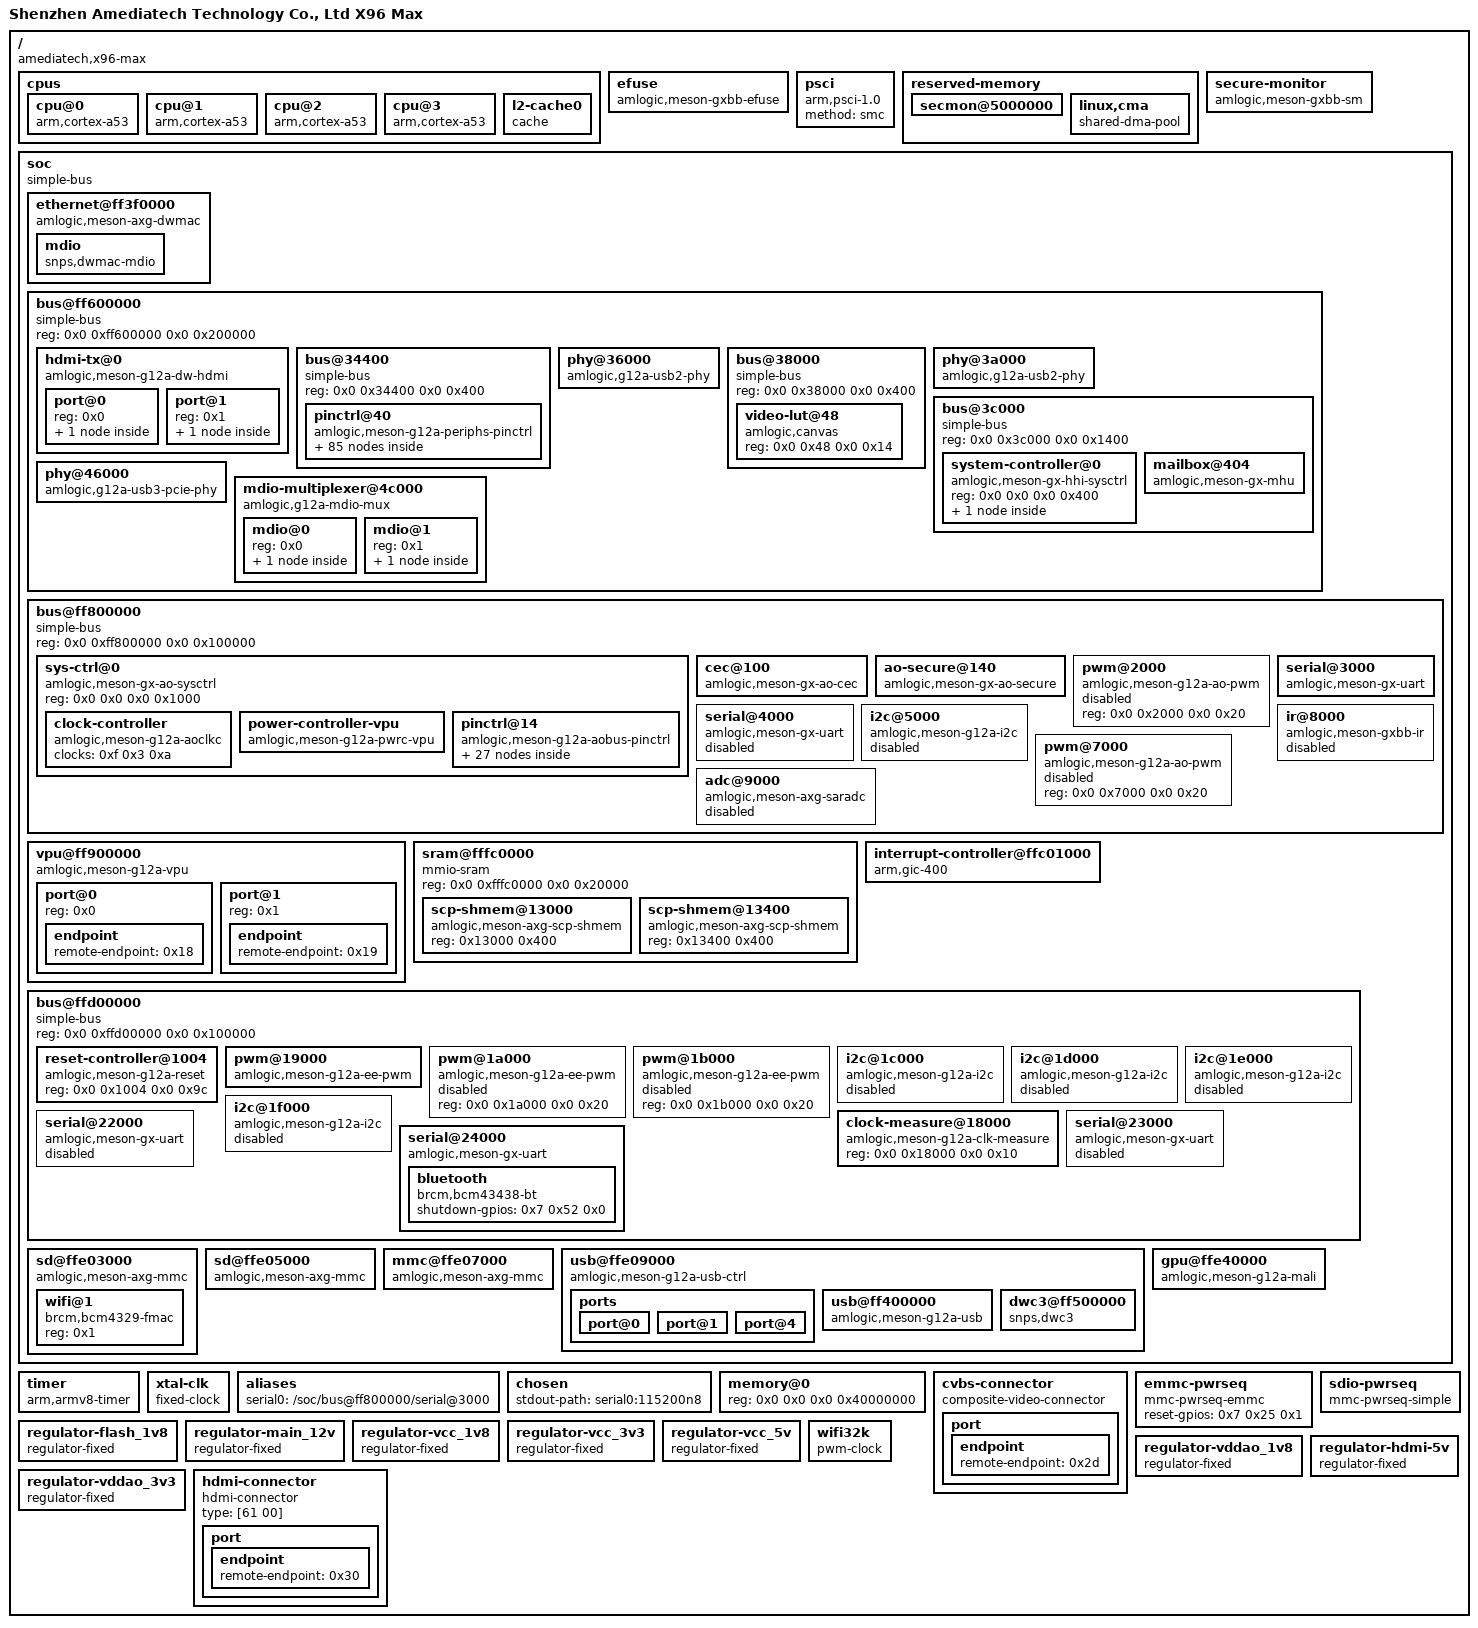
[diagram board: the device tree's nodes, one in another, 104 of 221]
/dts-v1/;

/ {
	compatible = "amediatech,x96-max", "amlogic,u200", "amlogic,g12a";
	interrupt-parent = <0x1>;
	#address-cells = <0x2>;
	#size-cells = <0x2>;
	model = "Shenzhen Amediatech Technology Co., Ltd X96 Max";

	cpus {
		#address-cells = <0x2>;
		#size-cells = <0x0>;

		cpu@0 {
			device_type = "cpu";
			compatible = "arm,cortex-a53", "arm,armv8";
			reg = <0x0 0x0>;
			enable-method = "psci";
			next-level-cache = <0x2>;
		};

		cpu@1 {
			device_type = "cpu";
			compatible = "arm,cortex-a53", "arm,armv8";
			reg = <0x0 0x1>;
			enable-method = "psci";
			next-level-cache = <0x2>;
		};

		cpu@2 {
			device_type = "cpu";
			compatible = "arm,cortex-a53", "arm,armv8";
			reg = <0x0 0x2>;
			enable-method = "psci";
			next-level-cache = <0x2>;
		};

		cpu@3 {
			device_type = "cpu";
			compatible = "arm,cortex-a53", "arm,armv8";
			reg = <0x0 0x3>;
			enable-method = "psci";
			next-level-cache = <0x2>;
		};

		l2-cache0 {
			compatible = "cache";
			phandle = <0x2>;
		};
	};

	efuse {
		compatible = "amlogic,meson-gxbb-efuse";
		clocks = <0x3 0x6a>;
		#address-cells = <0x1>;
		#size-cells = <0x1>;
		read-only;
	};

	psci {
		compatible = "arm,psci-1.0";
		method = "smc";
	};

	reserved-memory {
		#address-cells = <0x2>;
		#size-cells = <0x2>;
		ranges;

		secmon@5000000 {
			reg = <0x0 0x5000000 0x0 0x300000>;
			no-map;
		};

		linux,cma {
			compatible = "shared-dma-pool";
			reusable;
			size = <0x0 0x10000000>;
			alignment = <0x0 0x400000>;
			linux,cma-default;
		};
	};

	secure-monitor {
		compatible = "amlogic,meson-gxbb-sm";
	};

	soc {
		compatible = "simple-bus";
		#address-cells = <0x2>;
		#size-cells = <0x2>;
		ranges;

		ethernet@ff3f0000 {
			compatible = "amlogic,meson-axg-dwmac", "snps,dwmac-3.710", "snps,dwmac";
			reg = <0x0 0xff3f0000 0x0 0x10000 0x0 0xff634540 0x0 0x8>;
			interrupts = <0x0 0x8 0x4>;
			interrupt-names = "macirq";
			clocks = <0x3 0x26 0x3 0x2 0x3 0xd>;
			clock-names = "stmmaceth", "clkin0", "clkin1";
			status = "okay";
			pinctrl-0 = <0x4 0x5>;
			pinctrl-names = "default";
			phy-mode = "rgmii";
			phy-handle = <0x6>;
			amlogic,tx-delay-ns = <0x2>;
			snps,reset-gpio = <0x7 0xe 0x0>;
			snps,reset-delays-us = <0x0 0x2710 0xf4240>;
			snps,reset-active-low;

			mdio {
				#address-cells = <0x1>;
				#size-cells = <0x0>;
				compatible = "snps,dwmac-mdio";
				phandle = <0x11>;
			};
		};

		bus@ff600000 {
			compatible = "simple-bus";
			reg = <0x0 0xff600000 0x0 0x200000>;
			#address-cells = <0x2>;
			#size-cells = <0x2>;
			ranges = <0x0 0x0 0x0 0xff600000 0x0 0x200000>;

			hdmi-tx@0 {
				compatible = "amlogic,meson-g12a-dw-hdmi";
				reg = <0x0 0x0 0x0 0x10000>;
				interrupts = <0x0 0x39 0x1>;
				resets = <0x8 0x13 0x8 0x42 0x8 0x4f>;
				reset-names = "hdmitx_apb", "hdmitx", "hdmitx_phy";
				clocks = <0x3 0xa8 0x3 0x35 0x3 0x3a>;
				clock-names = "isfr", "iahb", "venci";
				#address-cells = <0x1>;
				#size-cells = <0x0>;
				status = "okay";
				pinctrl-0 = <0x9 0xa>;
				pinctrl-names = "default";
				hdmi-supply = <0xb>;
				phandle = <0x15>;

				port@0 {
					reg = <0x0>;

					endpoint {
						remote-endpoint = <0xc>;
						phandle = <0x19>;
					};
				};

				port@1 {
					reg = <0x1>;

					endpoint {
						remote-endpoint = <0xd>;
						phandle = <0x30>;
					};
				};
			};

			bus@34400 {
				compatible = "simple-bus";
				reg = <0x0 0x34400 0x0 0x400>;
				#address-cells = <0x2>;
				#size-cells = <0x2>;
				ranges = <0x0 0x0 0x0 0x34400 0x0 0x400>;

				pinctrl@40 {
					compatible = "amlogic,meson-g12a-periphs-pinctrl";
					#address-cells = <0x2>;
					#size-cells = <0x2>;
					ranges;
					phandle = <0xe>;

					bank@40 {
						reg = <0x0 0x40 0x0 0x4c 0x0 0xe8 0x0 0x18 0x0 0x120 0x0 0x18 0x0 0x2c0 0x0 0x40 0x0 0x340 0x0 0x1c>;
						reg-names = "gpio", "pull", "pull-enable", "mux", "ds";
						gpio-controller;
						#gpio-cells = <0x2>;
						gpio-ranges = <0xe 0x0 0x0 0x56>;
						phandle = <0x7>;
					};

					cec_ao_a_h {
						phandle = <0x14>;

						mux {
							groups = "cec_ao_a_h";
							function = "cec_ao_a_h";
							bias-disable;
						};
					};

					emmc {
						phandle = <0x24>;

						mux {
							groups = "emmc_nand_d0", "emmc_nand_d1", "emmc_nand_d2", "emmc_nand_d3", "emmc_nand_d4", "emmc_nand_d5", "emmc_nand_d6", "emmc_nand_d7", "emmc_clk", "emmc_cmd";
							function = "emmc";
							bias-pull-up;
						};
					};

					emmc-ds {
						phandle = <0x25>;

						mux {
							groups = "emmc_nand_ds";
							function = "emmc";
							bias-pull-down;
						};
					};

					emmc_clk_gate {
						phandle = <0x26>;

						mux {
							groups = "BOOT_8";
							function = "gpio_periphs";
							bias-pull-down;
						};
					};

					eth-leds {

						mux {
							groups = "eth_link_led", "eth_act_led";
							function = "eth";
							bias-disable;
						};
					};

					eth-rmii {
						phandle = <0x4>;

						mux {
							groups = "eth_mdio", "eth_mdc", "eth_rgmii_rx_clk", "eth_rx_dv", "eth_rxd0", "eth_rxd1", "eth_txen", "eth_txd0", "eth_txd1";
							function = "eth";
							bias-disable;
						};
					};

					eth-rgmii {
						phandle = <0x5>;

						mux {
							groups = "eth_rxd2_rgmii", "eth_rxd3_rgmii", "eth_rgmii_tx_clk", "eth_txd2_rgmii", "eth_txd3_rgmii";
							function = "eth";
							bias-disable;
						};
					};

					i2c0_c {

						mux {
							groups = "i2c0_sda_c", "i2c0_sck_c";
							function = "i2c0";
							drive-strength = <0x2>;
						};
					};

					i2c0_z_0_1 {

						mux {
							groups = "i2c0_sda_z0", "i2c0_sck_z1";
							function = "i2c0";
							drive-strength = <0x2>;
						};
					};

					i2c0_z_7_8 {

						mux {
							groups = "i2c0_sda_z7", "i2c0_sck_z8";
							function = "i2c0";
							drive-strength = <0x2>;
						};
					};

					i2c1_x {

						mux {
							groups = "i2c1_sda_x", "i2c1_sck_x";
							function = "i2c1";
							drive-strength = <0x2>;
						};
					};

					i2c1_h_3_4 {

						mux {
							groups = "i2c1_sda_h2", "i2c1_sck_h3";
							function = "i2c1";
							drive-strength = <0x2>;
						};
					};

					i2c1_h_6_7 {

						mux {
							groups = "i2c1_sda_h6", "i2c1_sck_h7";
							function = "i2c1";
							drive-strength = <0x2>;
						};
					};

					i2c2_x {

						mux {
							groups = "i2c2_sda_x", "i2c2_sck_x";
							function = "i2c2";
							drive-strength = <0x2>;
						};
					};

					i2c2_z {

						mux {
							groups = "i2c2_sda_z", "i2c2_sck_z";
							function = "i2c2";
							drive-strength = <0x2>;
						};
					};

					i2c3_h {

						mux {
							groups = "i2c3_sda_h", "i2c3_sck_h";
							function = "i2c3";
							drive-strength = <0x2>;
						};
					};

					i2c3_a {

						mux {
							groups = "i2c3_sda_a", "i2c3_sck_a";
							function = "i2c3";
							drive-strength = <0x2>;
						};
					};

					hdmitx_ddc {
						phandle = <0xa>;

						mux {
							groups = "hdmitx_sda", "hdmitx_sck";
							function = "hdmitx";
							bias-disable;
						};
					};

					hdmitx_hpd {
						phandle = <0x9>;

						mux {
							groups = "hdmitx_hpd_in";
							function = "hdmitx";
							bias-disable;
						};
					};

					sdcard_c {
						phandle = <0x22>;

						mux {
							groups = "sdcard_d0_c", "sdcard_d1_c", "sdcard_d2_c", "sdcard_d3_c", "sdcard_cmd_c", "sdcard_clk_c";
							function = "sdcard";
							bias-pull-up;
						};
					};

					sdcard_clk_gate_c {
						phandle = <0x23>;

						mux {
							groups = "GPIOC_4";
							function = "gpio_periphs";
							bias-pull-down;
						};
					};

					sdcard_z {

						mux {
							groups = "sdcard_d0_z", "sdcard_d1_z", "sdcard_d2_z", "sdcard_d3_z", "sdcard_cmd_z", "sdcard_clk_z";
							function = "sdcard";
							bias-pull-up;
						};
					};

					sdcard_clk_gate_z {

						mux {
							groups = "GPIOZ_6";
							function = "gpio_periphs";
							bias-pull-down;
						};
					};

					sdio {
						phandle = <0x1d>;

						mux {
							groups = "sdio_d0", "sdio_d1", "sdio_d2", "sdio_d3", "sdio_cmd", "sdio_clk";
							function = "sdio";
							bias-disable;
						};
					};

					sdio_clk_gate {
						phandle = <0x1e>;

						mux {
							groups = "GPIOX_4";
							function = "gpio_periphs";
							bias-pull-down;
						};
					};

					pwm_a {

						mux {
							groups = "pwm_a";
							function = "pwm_a";
							bias-disable;
						};
					};

					pwm_b_x7 {

						mux {
							groups = "pwm_b_x7";
							function = "pwm_b";
							bias-disable;
						};
					};

					pwm_b_x19 {

						mux {
							groups = "pwm_b_x19";
							function = "pwm_b";
							bias-disable;
						};
					};

					pwm_c_c {

						mux {
							groups = "pwm_c_c";
							function = "pwm_c";
							bias-disable;
						};
					};

					pwm_c_x5 {

						mux {
							groups = "pwm_c_x5";
							function = "pwm_c";
							bias-disable;
						};
					};

					pwm_c_x8 {

						mux {
							groups = "pwm_c_x8";
							function = "pwm_c";
							bias-disable;
						};
					};

					pwm_d_x3 {

						mux {
							groups = "pwm_d_x3";
							function = "pwm_d";
							bias-disable;
						};
					};

					pwm_d_x6 {

						mux {
							groups = "pwm_d_x6";
							function = "pwm_d";
							bias-disable;
						};
					};

					pwm_e {
						phandle = <0x1a>;

						mux {
							groups = "pwm_e";
							function = "pwm_e";
							bias-disable;
						};
					};

					pwm_f_x {

						mux {
							groups = "pwm_f_x";
							function = "pwm_f";
							bias-disable;
						};
					};

					pwm_f_h {

						mux {
							groups = "pwm_f_h";
							function = "pwm_f";
							bias-disable;
						};
					};

					uart_a {
						phandle = <0x1b>;

						mux {
							groups = "uart_a_tx", "uart_a_rx";
							function = "uart_a";
							bias-disable;
						};
					};

					uart_a_cts_rts {
						phandle = <0x1c>;

						mux {
							groups = "uart_a_cts", "uart_a_rts";
							function = "uart_a";
							bias-disable;
						};
					};

					uart_ao_a_c {

						mux {
							groups = "uart_ao_a_rx_c", "uart_ao_a_tx_c";
							function = "uart_ao_a_c";
							bias-disable;
						};
					};

					uart_b {

						mux {
							groups = "uart_b_tx", "uart_b_rx";
							function = "uart_b";
							bias-disable;
						};
					};

					uart_c {

						mux {
							groups = "uart_c_tx", "uart_c_rx";
							function = "uart_c";
							bias-disable;
						};
					};

					uart_c_cts_rts {

						mux {
							groups = "uart_c_cts", "uart_c_rts";
							function = "uart_c";
							bias-disable;
						};
					};
				};
			};

			phy@36000 {
				compatible = "amlogic,g12a-usb2-phy";
				reg = <0x0 0x36000 0x0 0x2000>;
				clocks = <0xf>;
				clock-names = "xtal";
				resets = <0x8 0x30>;
				reset-names = "phy";
				dr_mode = "host";
				#phy-cells = <0x0>;
				phandle = <0x2a>;
			};

			bus@38000 {
				compatible = "simple-bus";
				reg = <0x0 0x38000 0x0 0x400>;
				#address-cells = <0x2>;
				#size-cells = <0x2>;
				ranges = <0x0 0x0 0x0 0x38000 0x0 0x400>;

				video-lut@48 {
					compatible = "amlogic,canvas";
					reg = <0x0 0x48 0x0 0x14>;
					phandle = <0x16>;
				};
			};

			phy@3a000 {
				compatible = "amlogic,g12a-usb2-phy";
				reg = <0x0 0x3a000 0x0 0x2000>;
				clocks = <0xf>;
				clock-names = "xtal";
				resets = <0x8 0x31>;
				reset-names = "phy";
				dr_mode = "otg";
				#phy-cells = <0x0>;
				phandle = <0x2b>;
			};

			bus@3c000 {
				compatible = "simple-bus";
				reg = <0x0 0x3c000 0x0 0x1400>;
				#address-cells = <0x2>;
				#size-cells = <0x2>;
				ranges = <0x0 0x0 0x0 0x3c000 0x0 0x1400>;

				system-controller@0 {
					compatible = "amlogic,meson-gx-hhi-sysctrl", "simple-mfd", "syscon";
					reg = <0x0 0x0 0x0 0x400>;
					phandle = <0x12>;

					clock-controller {
						compatible = "amlogic,g12a-clkc";
						#clock-cells = <0x1>;
						clocks = <0xf>;
						clock-names = "xtal";
						phandle = <0x3>;
					};
				};

				mailbox@404 {
					compatible = "amlogic,meson-gx-mhu", "amlogic,meson-gxbb-mhu";
					reg = <0x0 0x404 0x0 0x4c>;
					interrupts = <0x0 0xd0 0x1 0x0 0xd1 0x1 0x0 0xd2 0x1>;
					clocks = <0x10 0x9>;
					clock-names = "pclk";
					#mbox-cells = <0x1>;
				};
			};

			phy@46000 {
				compatible = "amlogic,g12a-usb3-pcie-phy";
				reg = <0x0 0x46000 0x0 0x2000>;
				clocks = <0x3 0xb5>;
				clock-names = "ref_clk";
				resets = <0x8 0xc 0x8 0xe 0x8 0xf>;
				assigned-clocks = <0x3 0xb5>;
				assigned-clock-rates = <0x5f5e100>;
				dr_mode = "host";
				#phy-cells = <0x1>;
				phandle = <0x2c>;
			};

			mdio-multiplexer@4c000 {
				compatible = "amlogic,g12a-mdio-mux";
				reg = <0x0 0x4c000 0x0 0xa4>;
				clocks = <0x3 0x13 0xf 0x3 0xb1>;
				clock-names = "pclk", "clkin0", "clkin1";
				mdio-parent-bus = <0x11>;
				#address-cells = <0x1>;
				#size-cells = <0x0>;

				mdio@0 {
					reg = <0x0>;
					#address-cells = <0x1>;
					#size-cells = <0x0>;

					ethernet-phy@0 {
						compatible = "ethernet-phy-id001c.c916", "ethernet-phy-ieee802.3-c22";
						reg = <0x0>;
						max-speed = <0x3e8>;
						eee-broken-1000t;
						phandle = <0x6>;
					};
				};

				mdio@1 {
					reg = <0x1>;
					#address-cells = <0x1>;
					#size-cells = <0x0>;

					ethernet_phy@8 {
						compatible = "ethernet-phy-id0180.3300", "ethernet-phy-ieee802.3-c22";
						reg = <0x8>;
						max-speed = <0x64>;
					};
				};
			};
		};

		bus@ff800000 {
			compatible = "simple-bus";
			reg = <0x0 0xff800000 0x0 0x100000>;
			#address-cells = <0x2>;
			#size-cells = <0x2>;
			ranges = <0x0 0x0 0x0 0xff800000 0x0 0x100000>;

			sys-ctrl@0 {
				compatible = "amlogic,meson-gx-ao-sysctrl", "simple-mfd", "syscon";
				reg = <0x0 0x0 0x0 0x1000>;
				#address-cells = <0x2>;
				#size-cells = <0x2>;
				ranges = <0x0 0x0 0x0 0x0 0x0 0x1000>;

				clock-controller {
					compatible = "amlogic,meson-g12a-aoclkc";
					#clock-cells = <0x1>;
					#reset-cells = <0x1>;
					clocks = <0xf 0x3 0xa>;
					clock-names = "xtal", "mpeg-clk";
					phandle = <0x10>;
				};

				power-controller-vpu {
					compatible = "amlogic,meson-g12a-pwrc-vpu";
					#power-domain-cells = <0x0>;
					amlogic,hhi-sysctrl = <0x12>;
					resets = <0x8 0x5 0x8 0xa 0x8 0xd 0x8 0x25 0x8 0x85 0x8 0x86 0x8 0x87 0x8 0x89 0x8 0x8c 0x8 0x8d 0x8 0xe7>;
					clocks = <0x3 0x74 0x3 0x7c>;
					clock-names = "vpu", "vapb";
					assigned-clocks = <0x3 0x6e 0x3 0x70 0x3 0x74 0x3 0x75 0x3 0x77 0x3 0x7b>;
					assigned-clock-parents = <0x3 0x3 0x0 0x3 0x70 0x3 0x4 0x0 0x3 0x77>;
					assigned-clock-rates = <0x0 0x27bc86aa 0x0 0x0 0xee6b280 0x0>;
					phandle = <0x17>;
				};

				pinctrl@14 {
					compatible = "amlogic,meson-g12a-aobus-pinctrl";
					#address-cells = <0x2>;
					#size-cells = <0x2>;
					ranges;
					phandle = <0x13>;

					bank@14 {
						reg = <0x0 0x14 0x0 0x8 0x0 0x1c 0x0 0x8 0x0 0x24 0x0 0x14>;
						reg-names = "mux", "ds", "gpio";
						gpio-controller;
						#gpio-cells = <0x2>;
						gpio-ranges = <0x13 0x0 0x0 0xf>;
					};

					uart_a_ao {

						mux {
							groups = "uart_ao_a_tx", "uart_ao_a_rx";
							function = "uart_ao_a";
							bias-disable;
						};
					};

					uart_ao_a_cts_rts {

						mux {
							groups = "uart_ao_a_cts", "uart_ao_a_rts";
							function = "uart_ao_a";
							bias-disable;
						};
					};

					remote_input_ao {

						mux {
							groups = "remote_ao_input";
							function = "remote_ao_input";
							bias-disable;
						};
					};

					remote_output_ao {

						mux {
							groups = "remote_ao_out";
							function = "remote_ao_out";
							bias-disable;
						};
					};

					pwm_ao_a {

						mux {
							groups = "pwm_ao_a";
							function = "pwm_ao_a";
							bias-disable;
						};
					};

					pwm_ao_b {

						mux {
							groups = "pwm_ao_b";
							function = "pwm_ao_b";
							bias-disable;
						};
					};

					pwm_ao_c_4 {

						mux {
							groups = "pwm_ao_c_4";
							function = "pwm_ao_c";
							bias-disable;
						};
					};

					pwm_ao_c_6 {

						mux {
							groups = "pwm_ao_c_6";
							function = "pwm_ao_c";
							bias-disable;
						};
					};

					pwm_ao_d_5 {

						mux {
							groups = "pwm_ao_d_5";
							function = "pwm_ao_d";
							bias-disable;
						};
					};

					pwm_ao_d_10 {

						mux {
							groups = "pwm_ao_d_10";
							function = "pwm_ao_d";
							bias-disable;
						};
					};

					pwm_ao_d_e {

						mux {
							groups = "pwm_ao_d_e";
							function = "pwm_ao_d";
							bias-disable;
						};
					};

					ao_i2c_pins {

						mux {
							groups = "i2c_ao_sck", "i2c_ao_sda";
							function = "i2c_ao";
							drive-strength = <0x2>;
						};
					};

					ao_i2c_e {

						mux {
							groups = "i2c_ao_sck_e", "i2c_ao_sda_e";
							function = "i2c_ao";
							drive-strength = <0x2>;
						};
					};
				};
			};

			cec@100 {
				compatible = "amlogic,meson-gx-ao-cec", "amlogic,meson-g12a-ao-cec";
				reg = <0x0 0x100 0x0 0x14>;
				interrupts = <0x0 0xc7 0x1>;
				clocks = <0x10 0x1b>;
				clock-names = "core";
				status = "okay";
				pinctrl-0 = <0x14>;
				pinctrl-names = "default";
				hdmi-phandle = <0x15>;
			};

			ao-secure@140 {
				compatible = "amlogic,meson-gx-ao-secure", "syscon";
				reg = <0x0 0x140 0x0 0x140>;
				amlogic,has-chip-id;
			};

			pwm@2000 {
				compatible = "amlogic,meson-g12a-ao-pwm", "amlogic,meson-axo-ao-pwm";
				reg = <0x0 0x2000 0x0 0x20>;
				#pwm-cells = <0x3>;
				status = "disabled";
			};

			serial@3000 {
				compatible = "amlogic,meson-gx-uart", "amlogic,meson-ao-uart";
				reg = <0x0 0x3000 0x0 0x18>;
				interrupts = <0x0 0xc1 0x1>;
				clocks = <0xf 0x10 0x4 0xf>;
				clock-names = "xtal", "pclk", "baud";
				reset = <0x10 0x1>;
				status = "okay";
			};

			serial@4000 {
				compatible = "amlogic,meson-gx-uart", "amlogic,meson-ao-uart";
				reg = <0x0 0x4000 0x0 0x18>;
				interrupts = <0x0 0xc5 0x1>;
				clocks = <0xf 0x10 0x6 0xf>;
				clock-names = "xtal", "pclk", "baud";
				reset = <0x10 0x5>;
				status = "disabled";
			};

			i2c@5000 {
				compatible = "amlogic,meson-g12a-i2c";
				status = "disabled";
				reg = <0x0 0x5000 0x0 0x20>;
				interrupts = <0x0 0xc3 0x1 0x0 0xc9 0x1>;
				#address-cells = <0x1>;
				#size-cells = <0x0>;
				clocks = <0x3 0x18>;
				clock-names = "clk_i2c";
			};

			pwm@7000 {
				compatible = "amlogic,meson-g12a-ao-pwm", "amlogic,meson-axo-ao-pwm";
				reg = <0x0 0x7000 0x0 0x20>;
				#pwm-cells = <0x3>;
				status = "disabled";
			};

			ir@8000 {
				compatible = "amlogic,meson-gxbb-ir";
				reg = <0x0 0x8000 0x0 0x20>;
				interrupts = <0x0 0xc4 0x1>;
				status = "disabled";
			};

			adc@9000 {
				compatible = "amlogic,meson-axg-saradc", "amlogic,meson-saradc";
				reg = <0x0 0x9000 0x0 0x48>;
				#io-channel-cells = <0x1>;
				interrupts = <0x0 0xc8 0x1>;
				clocks = <0xf 0x10 0x8 0x10 0x12 0x10 0x10>;
				clock-names = "clkin", "core", "adc_clk", "adc_sel";
				status = "disabled";
			};
		};

		vpu@ff900000 {
			compatible = "amlogic,meson-g12a-vpu";
			reg = <0x0 0xff900000 0x0 0x100000 0x0 0xff63c000 0x0 0x1000>;
			reg-names = "vpu", "hhi";
			interrupts = <0x0 0x3 0x1>;
			#address-cells = <0x1>;
			#size-cells = <0x0>;
			amlogic,canvas = <0x16>;
			power-domains = <0x17>;

			port@0 {
				reg = <0x0>;

				endpoint {
					remote-endpoint = <0x18>;
					phandle = <0x2d>;
				};
			};

			port@1 {
				reg = <0x1>;

				endpoint {
					remote-endpoint = <0x19>;
					phandle = <0xc>;
				};
			};
		};

		sram@fffc0000 {
			compatible = "mmio-sram";
			reg = <0x0 0xfffc0000 0x0 0x20000>;
			#address-cells = <0x1>;
			#size-cells = <0x1>;
			ranges = <0x0 0x0 0xfffc0000 0x20000>;

			scp-shmem@13000 {
				compatible = "amlogic,meson-axg-scp-shmem";
				reg = <0x13000 0x400>;
			};

			scp-shmem@13400 {
				compatible = "amlogic,meson-axg-scp-shmem";
				reg = <0x13400 0x400>;
			};
		};

		interrupt-controller@ffc01000 {
			compatible = "arm,gic-400";
			reg = <0x0 0xffc01000 0x0 0x1000 0x0 0xffc02000 0x0 0x2000 0x0 0xffc04000 0x0 0x2000 0x0 0xffc06000 0x0 0x2000>;
			interrupt-controller;
			interrupts = <0x1 0x9 0xff04>;
			#interrupt-cells = <0x3>;
			#address-cells = <0x0>;
			phandle = <0x1>;
		};

		bus@ffd00000 {
			compatible = "simple-bus";
			reg = <0x0 0xffd00000 0x0 0x100000>;
			#address-cells = <0x2>;
			#size-cells = <0x2>;
			ranges = <0x0 0x0 0x0 0xffd00000 0x0 0x100000>;

			reset-controller@1004 {
				compatible = "amlogic,meson-g12a-reset", "amlogic,meson-axg-reset";
				reg = <0x0 0x1004 0x0 0x9c>;
				#reset-cells = <0x1>;
				phandle = <0x8>;
			};

			pwm@19000 {
				compatible = "amlogic,meson-g12a-ee-pwm", "amlogic,meson-gxbb-pwm";
				reg = <0x0 0x19000 0x0 0x20>;
				#pwm-cells = <0x3>;
				status = "okay";
				pinctrl-0 = <0x1a>;
				pinctrl-names = "default";
				phandle = <0x31>;
			};

			pwm@1a000 {
				compatible = "amlogic,meson-g12a-ee-pwm", "amlogic,meson-gxbb-pwm";
				reg = <0x0 0x1a000 0x0 0x20>;
				#pwm-cells = <0x3>;
				status = "disabled";
			};

			pwm@1b000 {
				compatible = "amlogic,meson-g12a-ee-pwm", "amlogic,meson-gxbb-pwm";
				reg = <0x0 0x1b000 0x0 0x20>;
				#pwm-cells = <0x3>;
				status = "disabled";
			};

			i2c@1c000 {
				compatible = "amlogic,meson-g12a-i2c", "amlogic,meson-axg-i2c";
				status = "disabled";
				reg = <0x0 0x1c000 0x0 0x20>;
				interrupts = <0x0 0x27 0x1>;
				#address-cells = <0x1>;
				#size-cells = <0x0>;
				clocks = <0x3 0x18>;
			};

			i2c@1d000 {
				compatible = "amlogic,meson-g12a-i2c", "amlogic,meson-axg-i2c";
				status = "disabled";
				reg = <0x0 0x1d000 0x0 0x20>;
				interrupts = <0x0 0xd7 0x1>;
				#address-cells = <0x1>;
				#size-cells = <0x0>;
				clocks = <0x3 0x18>;
			};

			i2c@1e000 {
				compatible = "amlogic,meson-g12a-i2c", "amlogic,meson-axg-i2c";
				status = "disabled";
				reg = <0x0 0x1e000 0x0 0x20>;
				interrupts = <0x0 0xd6 0x1>;
				#address-cells = <0x1>;
				#size-cells = <0x0>;
				clocks = <0x3 0x18>;
			};

			i2c@1f000 {
				compatible = "amlogic,meson-g12a-i2c", "amlogic,meson-axg-i2c";
				status = "disabled";
				reg = <0x0 0x1f000 0x0 0x20>;
				interrupts = <0x0 0x15 0x1>;
				#address-cells = <0x1>;
				#size-cells = <0x0>;
				clocks = <0x3 0x18>;
			};

			clock-measure@18000 {
				compatible = "amlogic,meson-g12a-clk-measure";
				reg = <0x0 0x18000 0x0 0x10>;
			};

			serial@22000 {
				compatible = "amlogic,meson-gx-uart";
				reg = <0x0 0x22000 0x0 0x18>;
				interrupts = <0x0 0x5d 0x1>;
				clocks = <0xf 0x3 0x2a 0xf>;
				clock-names = "xtal", "pclk", "baud";
				status = "disabled";
			};

			serial@23000 {
				compatible = "amlogic,meson-gx-uart";
				reg = <0x0 0x23000 0x0 0x18>;
				interrupts = <0x0 0x4b 0x1>;
				clocks = <0xf 0x3 0x2a 0xf>;
				clock-names = "xtal", "pclk", "baud";
				status = "disabled";
			};

			serial@24000 {
				compatible = "amlogic,meson-gx-uart";
				reg = <0x0 0x24000 0x0 0x18>;
				interrupts = <0x0 0x1a 0x1>;
				clocks = <0xf 0x3 0x1c 0xf>;
				clock-names = "xtal", "pclk", "baud";
				status = "okay";
				pinctrl-0 = <0x1b 0x1c>;
				pinctrl-names = "default";
				uart-has-rtscts;

				bluetooth {
					compatible = "brcm,bcm43438-bt";
					shutdown-gpios = <0x7 0x52 0x0>;
				};
			};
		};

		sd@ffe03000 {
			compatible = "amlogic,meson-axg-mmc";
			reg = <0x0 0xffe03000 0x0 0x800>;
			interrupts = <0x0 0xbd 0x1>;
			status = "okay";
			clocks = <0x3 0x21 0x3 0x3c 0x3 0x2>;
			clock-names = "core", "clkin0", "clkin1";
			resets = <0x8 0x2c>;
			pinctrl-0 = <0x1d>;
			pinctrl-1 = <0x1e>;
			pinctrl-names = "default", "clk-gate";
			#address-cells = <0x1>;
			#size-cells = <0x0>;
			bus-width = <0x4>;
			cap-sd-highspeed;
			max-frequency = <0x2faf080>;
			non-removable;
			disable-wp;
			mmc-pwrseq = <0x1f>;
			vmmc-supply = <0x20>;
			vqmmc-supply = <0x21>;

			wifi@1 {
				reg = <0x1>;
				compatible = "brcm,bcm4329-fmac";
			};
		};

		sd@ffe05000 {
			compatible = "amlogic,meson-axg-mmc";
			reg = <0x0 0xffe05000 0x0 0x800>;
			interrupts = <0x0 0xbe 0x1>;
			status = "okay";
			clocks = <0x3 0x22 0x3 0x3d 0x3 0x2>;
			clock-names = "core", "clkin0", "clkin1";
			resets = <0x8 0x2d>;
			pinctrl-0 = <0x22>;
			pinctrl-1 = <0x23>;
			pinctrl-names = "default", "clk-gate";
			bus-width = <0x4>;
			cap-sd-highspeed;
			max-frequency = <0x2faf080>;
			disable-wp;
			cd-gpios = <0x7 0x2f 0x1>;
			vmmc-supply = <0x20>;
			vqmmc-supply = <0x20>;
		};

		mmc@ffe07000 {
			compatible = "amlogic,meson-axg-mmc";
			reg = <0x0 0xffe07000 0x0 0x800>;
			interrupts = <0x0 0xbf 0x1>;
			status = "okay";
			clocks = <0x3 0x23 0x3 0x3e 0x3 0x2>;
			clock-names = "core", "clkin0", "clkin1";
			resets = <0x8 0x2e>;
			pinctrl-0 = <0x24 0x25>;
			pinctrl-1 = <0x26>;
			pinctrl-names = "default", "clk-gate";
			bus-width = <0x8>;
			cap-mmc-highspeed;
			mmc-ddr-1_8v;
			mmc-hs200-1_8v;
			max-frequency = <0xbebc200>;
			disable-wp;
			mmc-pwrseq = <0x27>;
			vmmc-supply = <0x28>;
			vqmmc-supply = <0x29>;
		};

		usb@ffe09000 {
			status = "okay";
			compatible = "amlogic,meson-g12a-usb-ctrl";
			reg = <0x0 0xffe09000 0x0 0xa0>;
			interrupts = <0x0 0x10 0x4>;
			#address-cells = <0x2>;
			#size-cells = <0x2>;
			ranges;
			clocks = <0x3 0x2f>;
			clock-names = "usb";
			resets = <0x8 0x22>;
			reset-names = "usb";

			ports {
				#address-cells = <0x1>;
				#size-cells = <0x0>;

				port@0 {
					reg = <0x0>;
					phys = <0x2a>;
				};

				port@1 {
					reg = <0x1>;
					phys = <0x2b>;
				};

				port@4 {
					reg = <0x4>;
					phys = <0x2c 0x4>;
					status = "okay";
				};
			};

			usb@ff400000 {
				compatible = "amlogic,meson-g12a-usb", "snps,dwc2";
				reg = <0x0 0xff400000 0x0 0x40000>;
				interrupts = <0x0 0x1f 0x4>;
				clocks = <0x3 0x37>;
				clock-names = "ddr";
				phys = <0x2b>;
				dr_mode = "peripheral";
				g-rx-fifo-size = <0xc0>;
				g-np-tx-fifo-size = <0x80>;
				g-tx-fifo-size = <0x80 0x80 0x10 0x10 0x10>;
				status = "okay";
			};

			dwc3@ff500000 {
				compatible = "snps,dwc3";
				reg = <0x0 0xff500000 0x0 0x100000>;
				interrupts = <0x0 0x1e 0x4>;
				dr_mode = "host";
				snps,dis_u2_susphy_quirk;
				snps,quirk-frame-length-adjustment;
			};
		};

		gpu@ffe40000 {
			compatible = "amlogic,meson-g12a-mali", "arm,mali-g31";
			reg = <0x0 0xffe40000 0x0 0x40000>;
			interrupt-parent = <0x1>;
			interrupts = <0x0 0xa0 0x4 0x0 0xa1 0x4 0x0 0xa2 0x4>;
			interrupt-names = "gpu", "mmu", "job";
			clocks = <0x3 0xaf>;
			resets = <0x8 0x14 0x8 0x4e>;
			assigned-clocks = <0x3 0xa9 0x3 0xab 0x3 0xaf>;
			assigned-clock-parents = <0x3 0x3 0x0 0x3 0xab>;
			assigned-clock-rates = <0x0 0x27bc86aa 0x0>;
		};
	};

	timer {
		compatible = "arm,armv8-timer";
		interrupts = <0x1 0xd 0xff08 0x1 0xe 0xff08 0x1 0xb 0xff08 0x1 0xa 0xff08>;
	};

	xtal-clk {
		compatible = "fixed-clock";
		clock-frequency = <0x16e3600>;
		clock-output-names = "xtal";
		#clock-cells = <0x0>;
		phandle = <0xf>;
	};

	aliases {
		serial0 = "/soc/bus@ff800000/serial@3000";
	};

	chosen {
		stdout-path = "serial0:115200n8";
	};

	memory@0 {
		device_type = "memory";
		reg = <0x0 0x0 0x0 0x40000000>;
	};

	cvbs-connector {
		compatible = "composite-video-connector";

		port {

			endpoint {
				remote-endpoint = <0x2d>;
				phandle = <0x18>;
			};
		};
	};

	emmc-pwrseq {
		compatible = "mmc-pwrseq-emmc";
		reset-gpios = <0x7 0x25 0x1>;
		phandle = <0x27>;
	};

	sdio-pwrseq {
		compatible = "mmc-pwrseq-simple";
		reset-gpios = <0x7 0x47 0x1>;
		clocks = <0x2e>;
		clock-names = "ext_clock";
		phandle = <0x1f>;
	};

	regulator-flash_1v8 {
		compatible = "regulator-fixed";
		regulator-name = "FLASH_1V8";
		regulator-min-microvolt = <0x1b7740>;
		regulator-max-microvolt = <0x1b7740>;
		vin-supply = <0x28>;
		regulator-always-on;
		phandle = <0x29>;
	};

	regulator-main_12v {
		compatible = "regulator-fixed";
		regulator-name = "12V";
		regulator-min-microvolt = <0xb71b00>;
		regulator-max-microvolt = <0xb71b00>;
		regulator-always-on;
		phandle = <0x2f>;
	};

	regulator-vcc_1v8 {
		compatible = "regulator-fixed";
		regulator-name = "VCC_1V8";
		regulator-min-microvolt = <0x1b7740>;
		regulator-max-microvolt = <0x1b7740>;
		vin-supply = <0x28>;
		regulator-always-on;
	};

	regulator-vcc_3v3 {
		compatible = "regulator-fixed";
		regulator-name = "VCC_3V3";
		regulator-min-microvolt = <0x325aa0>;
		regulator-max-microvolt = <0x325aa0>;
		vin-supply = <0x20>;
		regulator-always-on;
		phandle = <0x28>;
	};

	regulator-vcc_5v {
		compatible = "regulator-fixed";
		regulator-name = "VCC_5V";
		regulator-min-microvolt = <0x4c4b40>;
		regulator-max-microvolt = <0x4c4b40>;
		vin-supply = <0x2f>;
		gpio = <0x7 0x18 0x0>;
		enable-active-high;
		regulator-always-on;
	};

	regulator-vddao_1v8 {
		compatible = "regulator-fixed";
		regulator-name = "VDDAO_1V8";
		regulator-min-microvolt = <0x1b7740>;
		regulator-max-microvolt = <0x1b7740>;
		vin-supply = <0x20>;
		regulator-always-on;
		phandle = <0x21>;
	};

	regulator-vddao_3v3 {
		compatible = "regulator-fixed";
		regulator-name = "VDDAO_3V3";
		regulator-min-microvolt = <0x325aa0>;
		regulator-max-microvolt = <0x325aa0>;
		vin-supply = <0x2f>;
		regulator-always-on;
		phandle = <0x20>;
	};

	regulator-hdmi-5v {
		compatible = "regulator-fixed";
		regulator-name = "HDMI_5V";
		regulator-min-microvolt = <0x4c4b40>;
		regulator-max-microvolt = <0x4c4b40>;
		gpio = <0x7 0x18 0x0>;
		enable-active-high;
		regulator-always-on;
		phandle = <0xb>;
	};

	hdmi-connector {
		compatible = "hdmi-connector";
		type = [61 00];

		port {

			endpoint {
				remote-endpoint = <0x30>;
				phandle = <0xd>;
			};
		};
	};

	wifi32k {
		compatible = "pwm-clock";
		#clock-cells = <0x0>;
		clock-frequency = <0x8000>;
		pwms = <0x31 0x0 0x7736 0x0>;
		phandle = <0x2e>;
	};
};
